# STM32WLE4C8U6 register map
File version: 1.0
Registers are 32-bit, access not given, reset 0x0 unless marked. A register's access mark holds for its fields unless they carry their own. Offsets are from the block's base; [hi:lo] are bit positions; {n}, {i} and the like mark numbered series.

## DMAMUX1
Base 0x40020800
{0x0+4i} C{i}CR (i=0..13)
  [28:24] SYNC_ID, [23:19] NBREQ, [18:17] SPOL, [16] SE, [9] EGE, [8] SOIE, [31:7] s, [6:0] DMAREQ_ID
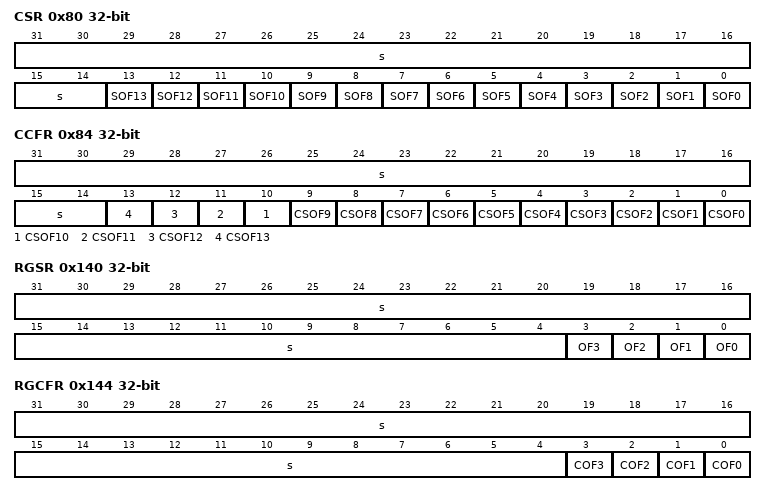
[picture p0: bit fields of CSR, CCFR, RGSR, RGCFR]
0x80 CSR
  [31:14] s, [n] SOF{n} (n=0..13)
0x84 CCFR
  [31:14] s, [n] CSOF{n} (n=0..13)
{0x100+4i} RG{i}CR (i=0..3)
  [23:19] GNBREQ, [18:17] GPOL, [16] GE, [8] OIE, [31:5] s, [4:0] SIG_ID
0x140 RGSR
  [31:4] s, [n] OF{n} (n=0..3)
0x144 RGCFR
  [31:4] s, [n] COF{n} (n=0..3)

## CRC
Base 0x40023000
0x00 DR
0x04 IDR
0x08 CR
  [7] REV_OUT, [6:5] REV_IN, [4:3] POLYSIZE, [31:1] s, [0] RESET
0x10 INIT
  [31:0] CRC_INIT
0x14 POL

## GPIO
Base 0x48000000
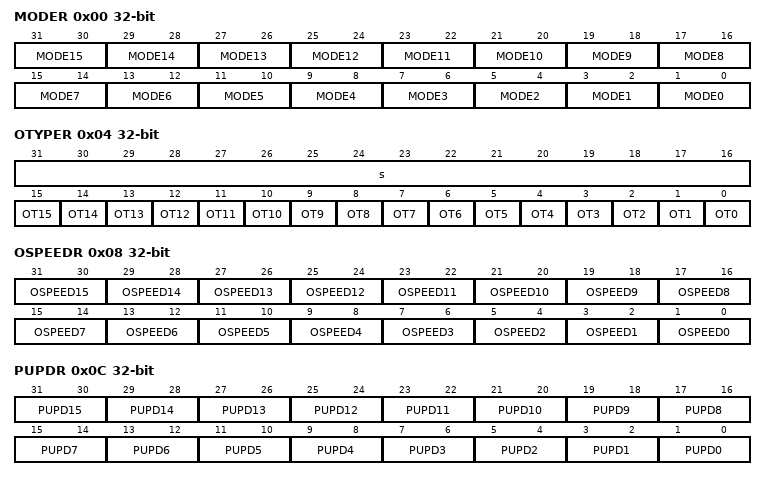
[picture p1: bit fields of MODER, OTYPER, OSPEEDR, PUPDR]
0x00 MODER
  [2n+1:2n] MODE{n} (n=0..15)
0x04 OTYPER
  [31:16] s, [n] OT{n} (n=0..15)
0x08 OSPEEDR
  [2n+1:2n] OSPEED{n} (n=0..15)
0x0C PUPDR
  [2n+1:2n] PUPD{n} (n=0..15)
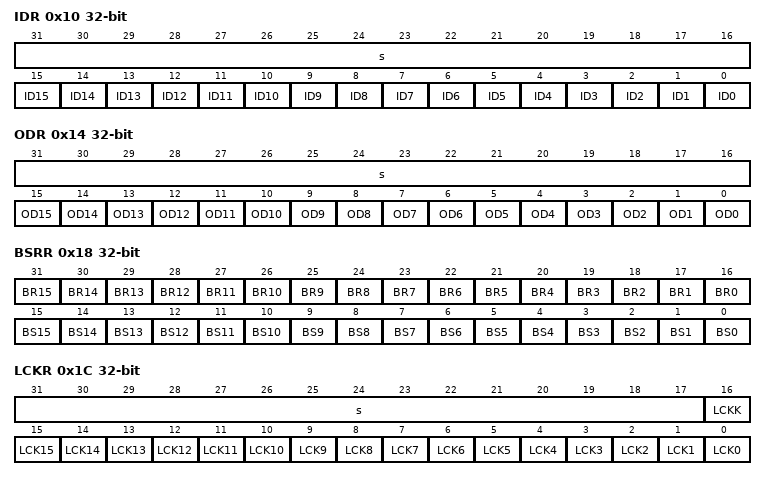
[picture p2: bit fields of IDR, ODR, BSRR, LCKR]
0x10 IDR
  [31:16] s, [n] ID{n} (n=0..15)
0x14 ODR
  [31:16] s, [n] OD{n} (n=0..15)
0x18 BSRR
  [n+16] BR{n} (n=0..15), [n] BS{n} (n=0..15)
0x1C LCKR
  [31:17] s, [16] LCKK, [n] LCK{n} (n=0..15)
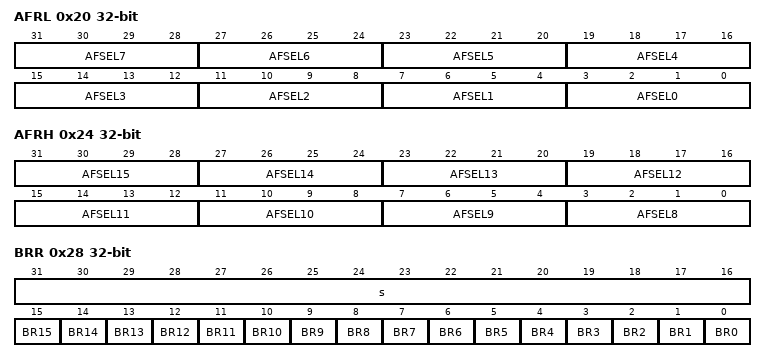
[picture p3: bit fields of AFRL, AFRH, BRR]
0x20 AFRL
  [4n+3:4n] AFSEL{n} (n=0..7)
0x24 AFRH
  [4n-29:4n-32] AFSEL{n} (n=8..15)
0x28 BRR
  [31:16] s, [n] BR{n} (n=0..15)
